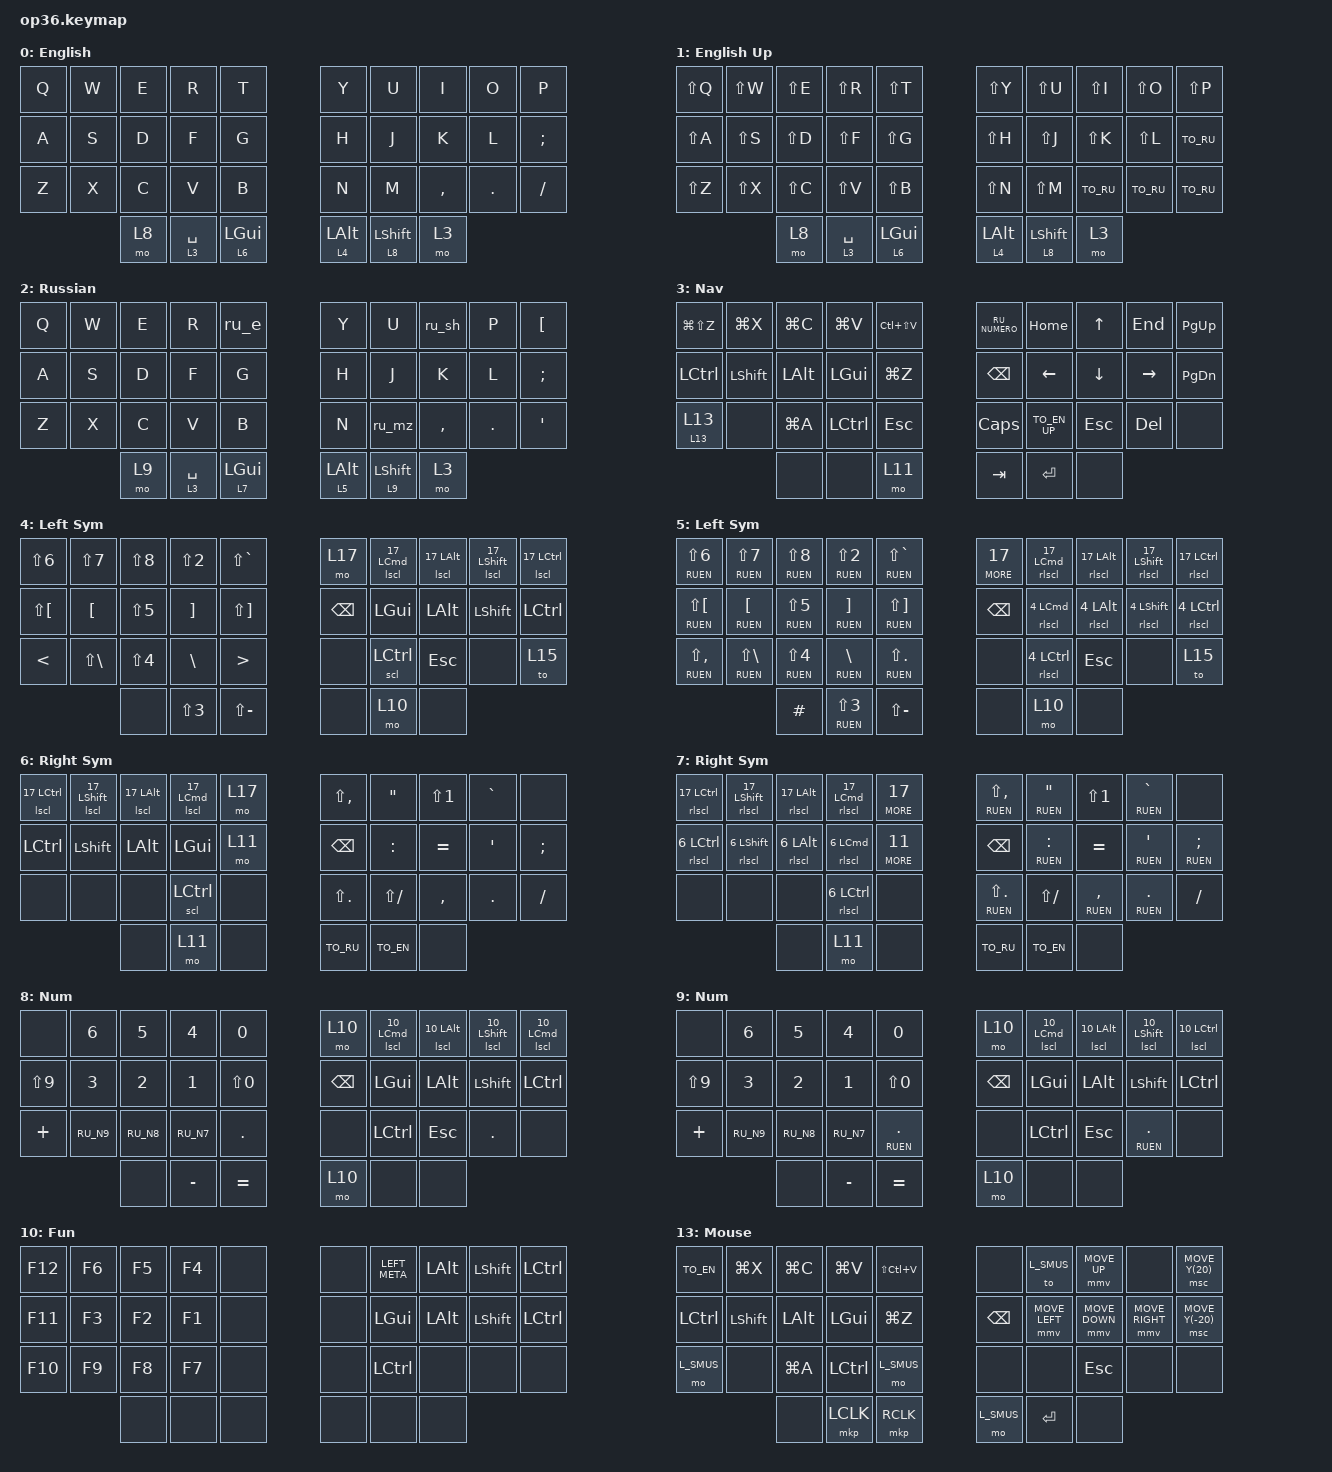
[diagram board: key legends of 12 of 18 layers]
#include "keys_ru.h"
#include <behaviors.dtsi>
#include <dt-bindings/zmk/bt.h>
#include <dt-bindings/zmk/keys.h>
#include <dt-bindings/zmk/outputs.h>
#include <dt-bindings/zmk/pointing.h>

#define L_SMUS 16
#define L_SHORTCUTS 17

&mt {
    quick-tap-ms = <200>;
    flavor = "tap-preferred";
    require-prior-idle-ms = <125>;
};

&sk {
    release-after-ms = <2000>;
    quick-release;
};

&sl { release-after-ms = <2000>; };

/ {
    behaviors {
        hml: home_row_mod_left {
            compatible = "zmk,behavior-hold-tap";
            #binding-cells = <2>;
            flavor = "balanced";
            require-prior-idle-ms = <150>;
            tapping-term-ms = <280>;
            quick-tap-ms = <175>;
            bindings = <&kp>, <&kp>;

            hold-trigger-key-positions = <5 6 7 8 9 15 16 17 18 19 25 26 27 28 29 33 34 35>;
            hold-trigger-on-release;
        };

        hmr: home_row_mod_right {
            compatible = "zmk,behavior-hold-tap";
            #binding-cells = <2>;
            flavor = "balanced";
            require-prior-idle-ms = <150>;
            tapping-term-ms = <280>;
            quick-tap-ms = <175>;
            bindings = <&kp>, <&kp>;

            hold-trigger-key-positions = <0 1 2 3 4 10 11 12 13 14 20 21 22 23 24 30 31 32>;
            hold-trigger-on-release;
        };

        mosk: mosk {
            compatible = "zmk,behavior-hold-tap";
            #binding-cells = <2>;
            flavor = "hold-preferred";
            require-prior-idle-ms = <150>;
            tapping-term-ms = <280>;
            quick-tap-ms = <175>;
            bindings = <&mo>, <&sk>;

            label = "MOSK";
        };

        mosl: mosl {
            compatible = "zmk,behavior-hold-tap";
            #binding-cells = <2>;
            flavor = "hold-preferred";
            require-prior-idle-ms = <150>;
            tapping-term-ms = <280>;
            quick-tap-ms = <175>;
            bindings = <&mo>, <&sl>;

            label = "MOSL";
        };

        ru_sh: ru_sh {
            compatible = "zmk,behavior-mod-morph";
            label = "RU_SH";
            bindings = <&kp I>, <&kp O>;

            #binding-cells = <0>;
            mods = <(MOD_LALT)>;
            keep-mods = <(MOD_LSFT)>;
        };

        ru_mz: ru_mz {
            compatible = "zmk,behavior-mod-morph";
            label = "RU_MZ";
            bindings = <&kp M>, <&kp RIGHT_BRACKET>;

            #binding-cells = <0>;
            mods = <(MOD_LALT)>;
            keep-mods = <(MOD_LSFT)>;
        };

        ru_e: ru_e {
            compatible = "zmk,behavior-mod-morph";
            label = "RU_E";
            bindings = <&kp T>, <&kp BACKSLASH>;

            #binding-cells = <0>;
            mods = <(MOD_LALT)>;
            keep-mods = <(MOD_LSFT)>;
        };

        ml: mod_layer {
            compatible = "zmk,behavior-hold-tap";
            label = "MOD_LAYER";
            bindings = <&mo>, <&kp>;

            #binding-cells = <2>;
            tapping-term-ms = <200>;
        };

        smmv: smmv {
            compatible = "zmk,behavior-input-two-axis";
            label = "SMMV";
            #binding-cells = <1>;
            x-input-code = <INPUT_REL_X>;
            y-input-code = <INPUT_REL_Y>;
            time-to-max-speed-ms = <300>;
            acceleration-exponent = <1>;
        };

        mrsk: mrsk {
            compatible = "zmk,behavior-hold-tap";
            #binding-cells = <2>;
            flavor = "balanced";
            require-prior-idle-ms = <150>;
            tapping-term-ms = <280>;
            quick-tap-ms = <175>;
            bindings = <&MORE>, <&sk>;

            label = "MRSK";
            hold-trigger-on-release;
            hold-trigger-key-positions = <5 15 16 6 5 6 7 8 9 15 16 17 18 19 25 26 27 28 29 33 34 35>;
        };

        tomo: to_mo_layer {
            compatible = "zmk,behavior-hold-tap";
            #binding-cells = <2>;
            flavor = "hold-preferred";

            // Без привязки к таймингам: огромный tapping-term фактически отключает
            // таймаут, поэтому hold/tap решается не временем, а нажатием другой
            // клавиши. Нажал клавишу мыши -> momentary-слой (&mo); одиночный тап
            // любой длительности без других клавиш -> полное переключение (&to).

            tapping-term-ms = <60000>;
            bindings = <&mo>, <&to>;

            label = "TOMO";
        };
    };

    combos { compatible = "zmk,combos"; };

    macros {
        RUEN: RUEN {
            compatible = "zmk,behavior-macro-one-param";
            #binding-cells = <1>;
            bindings = <&kp LA(LC(LS(LG(E)))) &macro_param_1to1 &kp MACRO_PLACEHOLDER &kp LS(LA(LC(LG(R))))>;
            label = "RUEN";
        };

        TO_RU: TO_RU {
            compatible = "zmk,behavior-macro";
            #binding-cells = <0>;
            bindings = <&kp LS(LG(LC(LA(R)))) &to 2>;
            label = "TO_RU";
        };

        TO_EN: TO_EN {
            compatible = "zmk,behavior-macro";
            #binding-cells = <0>;
            bindings = <&kp LS(LG(LC(LA(E)))) &to 0>;
            label = "TO_EN";
        };

        TO_EN_UP: TO_EN_UP {
            compatible = "zmk,behavior-macro";
            #binding-cells = <0>;
            bindings = <&kp LS(LG(LC(LA(E)))) &to 1>;
            label = "TO_EN_UP";
        };

        scl: shortcut_mod {
            compatible = "zmk,behavior-macro-one-param";
            #binding-cells = <1>;
            bindings =
                <&macro_press>,
                <&mo L_SHORTCUTS &macro_param_1to1 &kp MACRO_PLACEHOLDER>,
                <&macro_pause_for_release>,
                <&macro_release>,
                <&mo L_SHORTCUTS &macro_param_1to1 &kp MACRO_PLACEHOLDER>;

            label = "SHORTCUT_MOD";
        };

        lscl: lscl {
            compatible = "zmk,behavior-macro-two-param";
            #binding-cells = <2>;
            bindings =
                <&macro_press>,
                <&macro_param_1to1 &mo MACRO_PLACEHOLDER &macro_param_2to1 &kp MACRO_PLACEHOLDER>,
                <&macro_pause_for_release>,
                <&macro_release>,
                <&macro_param_2to1 &kp MACRO_PLACEHOLDER &macro_param_1to1 &mo MACRO_PLACEHOLDER>;

            label = "LSCL";
        };

        rscl: ru_shortcut_mod {
            compatible = "zmk,behavior-macro-one-param";
            #binding-cells = <1>;
            bindings =
                <&macro_tap>,
                <&kp LS(LG(LC(LA(E))))>,
                <&macro_press>,
                <&mo L_SHORTCUTS &macro_param_1to1 &kp MACRO_PLACEHOLDER>,
                <&macro_pause_for_release>,
                <&macro_release>,
                <&mo L_SHORTCUTS &macro_param_1to1 &kp MACRO_PLACEHOLDER>,
                <&macro_tap>,
                <&kp LS(LG(LC(LA(R))))>;

            label = "RU_SHORTCUT_MOD";
        };

        rlscl: ru_lscl {
            compatible = "zmk,behavior-macro-two-param";
            #binding-cells = <2>;
            bindings =
                <&macro_tap>,
                <&kp LS(LG(LC(LA(E))))>,
                <&macro_press>,
                <&macro_param_1to1 &mo MACRO_PLACEHOLDER &macro_param_2to1 &kp MACRO_PLACEHOLDER>,
                <&macro_pause_for_release>,
                <&macro_release>,
                <&macro_param_2to1 &kp MACRO_PLACEHOLDER &macro_param_1to1 &mo MACRO_PLACEHOLDER>,
                <&macro_tap>,
                <&kp LS(LG(LC(LA(R))))>;

            label = "RU_LSCL";
        };

        MORE: MORE {
            compatible = "zmk,behavior-macro-one-param";
            #binding-cells = <1>;
            bindings =
                <&macro_tap>,
                <&kp LA(LC(LS(LG(E))))>,
                <&macro_press>,
                <&macro_param_1to1 &mo MACRO_PLACEHOLDER>,
                <&macro_pause_for_release>,
                <&macro_release>,
                <&macro_param_1to1 &mo MACRO_PLACEHOLDER>,
                <&macro_tap>,
                <&kp LS(LA(LC(LG(R))))>;

            label = "MORE";
        };
    };

    keymap {
        compatible = "zmk,keymap";

        ENG {
            display-name = "English";
            bindings = <
  &kp Q  &kp W  &kp E  &kp R  &kp T                                              &kp Y               &kp U  &kp I      &kp O    &kp P
  &kp A  &kp S  &kp D  &kp F  &kp G                                              &kp H               &kp J  &kp K      &kp L    &kp SEMI
  &kp Z  &kp X  &kp C  &kp V  &kp B                                              &kp N               &kp M  &kp COMMA  &kp DOT  &kp FSLH
                       &mo 8  &lt 3 SPACE  &mosk 6 LEFT_GUI    &mosk 4 LEFT_ALT  &mosk 8 LEFT_SHIFT  &mo 3
            >;
        };

        ENG_UP {
            display-name = "English Up";
            bindings = <
  &kp LS(Q)  &kp LS(W)  &kp LS(E)  &kp LS(R)  &kp LS(T)                                          &kp LS(Y)           &kp LS(U)  &kp LS(I)  &kp LS(O)  &kp LS(P)
  &kp LS(A)  &kp LS(S)  &kp LS(D)  &kp LS(F)  &kp LS(G)                                          &kp LS(H)           &kp LS(J)  &kp LS(K)  &kp LS(L)  &TO_RU
  &kp LS(Z)  &kp LS(X)  &kp LS(C)  &kp LS(V)  &kp LS(B)                                          &kp LS(N)           &kp LS(M)  &TO_RU     &TO_RU     &TO_RU
                                   &mo 8      &lt 3 SPACE  &mosk 6 LEFT_GUI    &mosk 4 LEFT_ALT  &mosk 8 LEFT_SHIFT  &mo 3
            >;
        };

        RUS {
            display-name = "Russian";
            bindings = <
  &kp Q  &kp W  &kp E  &kp R  &ru_e                                              &kp Y               &kp U   &ru_sh     &kp P    &kp LEFT_BRACKET
  &kp A  &kp S  &kp D  &kp F  &kp G                                              &kp H               &kp J   &kp K      &kp L    &kp SEMI
  &kp Z  &kp X  &kp C  &kp V  &kp B                                              &kp N               &ru_mz  &kp COMMA  &kp DOT  &kp SQT
                       &mo 9  &lt 3 SPACE  &mosk 7 LEFT_GUI    &mosk 5 LEFT_ALT  &mosk 9 LEFT_SHIFT  &mo 3
            >;
        };

        NAV {
            bindings = <
  &kp LG(LS(Z))     &kp LG(X)       &kp LG(C)     &kp LG(V)         &kp LC(LS(V))                     &kp RU_NUMERO  &kp HOME        &kp UP      &kp END     &kp PAGE_UP
  &kp LEFT_CONTROL  &kp LEFT_SHIFT  &kp LEFT_ALT  &kp LEFT_GUI      &kp LG(Z)                         &kp BACKSPACE  &kp LEFT_ARROW  &kp DOWN    &kp RIGHT   &kp PAGE_DOWN
  &tomo 13 13       &none           &kp LG(A)     &kp LEFT_CONTROL  &kp ESC                           &kp CAPSLOCK   &TO_EN_UP       &kp ESCAPE  &kp DELETE  &none
                                                  &none             &none          &mo 11    &kp TAB  &kp ENTER      &none
            >;

            display-name = "Nav";
        };

        LSM_EN {
            bindings = <
  &kp LS(N6)            &kp LS(N7)         &kp LS(N8)        &kp LS(NUMBER_2)   &kp LS(GRAVE)                                  &mo 17         &lscl 17 LEFT_COMMAND  &lscl 17 LEFT_ALT  &lscl 17 LEFT_SHIFT  &lscl 17 LEFT_CONTROL
  &kp LS(LEFT_BRACKET)  &kp LEFT_BRACKET   &kp LS(NUMBER_5)  &kp RIGHT_BRACKET  &kp LS(RIGHT_BRACKET)                          &kp BACKSPACE  &kp LEFT_GUI           &kp LEFT_ALT       &kp LEFT_SHIFT       &kp LEFT_CONTROL
  &kp LESS_THAN         &kp LS(BACKSLASH)  &kp LS(NUMBER_4)  &kp BACKSLASH      &kp GREATER_THAN                               &none          &scl LEFT_CONTROL      &kp ESC            &none                &to 15
                                                             &none              &kp LS(NUMBER_3)       &kp LS(MINUS)    &none  &mo 10         &none
            >;

            label = "Left Sym";
        };

        LSM_RU {
            bindings = <
  &RUEN LS(N6)            &RUEN LS(N7)         &RUEN LS(N8)        &RUEN LS(NUMBER_2)   &RUEN LS(GRAVE)                                  &MORE 17       &rlscl 17 LEFT_COMMAND  &rlscl 17 LEFT_ALT  &rlscl 17 LEFT_SHIFT  &rlscl 17 LEFT_CONTROL
  &RUEN LS(LEFT_BRACKET)  &RUEN LEFT_BRACKET   &RUEN LS(NUMBER_5)  &RUEN RIGHT_BRACKET  &RUEN LS(RIGHT_BRACKET)                          &kp BACKSPACE  &rlscl 4 LEFT_COMMAND   &rlscl 4 LEFT_ALT   &rlscl 4 LEFT_SHIFT   &rlscl 4 LEFT_CONTROL
  &RUEN LS(COMMA)         &RUEN LS(BACKSLASH)  &RUEN LS(NUMBER_4)  &RUEN BACKSLASH      &RUEN LS(DOT)                                    &none          &rlscl 4 LEFT_CONTROL   &kp ESC             &none                 &to 15
                                                                   &kp HASH             &RUEN LS(NUMBER_3)       &kp LS(MINUS)    &none  &mo 10         &none
            >;

            label = "Left Sym";
        };

        RSM_EN {
            bindings = <
  &lscl 17 LEFT_CONTROL  &lscl 17 LEFT_SHIFT  &lscl 17 LEFT_ALT  &lscl 17 LEFT_COMMAND  &mo 17                   &kp LS(COMMA)  &kp DQT       &kp LS(N1)  &kp GRAVE         &none
  &kp LEFT_CONTROL       &kp LEFT_SHIFT       &kp LEFT_ALT       &kp LEFT_GUI           &mo 11                   &kp BACKSPACE  &kp COLON     &kp EQUAL   &kp SINGLE_QUOTE  &kp SEMI
  &none                  &none                &none              &scl LEFT_CONTROL      &none                    &kp LS(DOT)    &kp LS(FSLH)  &kp COMMA   &kp DOT           &kp FSLH
                                                                 &none                  &mo 11  &none    &TO_RU  &TO_EN         &none
            >;

            label = "Right Sym";
        };

        RSM_RU {
            bindings = <
  &rlscl 17 LEFT_CONTROL  &rlscl 17 LEFT_SHIFT  &rlscl 17 LEFT_ALT  &rlscl 17 LEFT_COMMAND  &MORE 17                   &RUEN LS(COMMA)  &RUEN DQT     &kp LS(N1)   &RUEN GRAVE         &none
  &rlscl 6 LEFT_CONTROL   &rlscl 6 LEFT_SHIFT   &rlscl 6 LEFT_ALT   &rlscl 6 LEFT_COMMAND   &MORE 11                   &kp BACKSPACE    &RUEN COLON   &kp EQUAL    &RUEN SINGLE_QUOTE  &RUEN SEMI
  &none                   &none                 &none               &rlscl 6 LEFT_CONTROL   &none                      &RUEN LS(DOT)    &kp LS(FSLH)  &RUEN COMMA  &RUEN DOT           &kp FSLH
                                                                    &none                   &mo 11    &none    &TO_RU  &TO_EN           &none
            >;

            label = "Right Sym";
        };

        NUM_EN {
            bindings = <
  &none       &kp N6        &kp NUMBER_5  &kp NUMBER_4  &kp N0                           &mo 10         &lscl 10 LEFT_COMMAND  &lscl 10 LEFT_ALT  &lscl 10 LEFT_SHIFT  &lscl 10 LEFT_COMMAND
  &kp LS(N9)  &kp NUMBER_3  &kp NUMBER_2  &kp N1        &kp LS(N0)                       &kp BACKSPACE  &kp LEFT_GUI           &kp LEFT_ALT       &kp LEFT_SHIFT       &kp LEFT_CONTROL
  &kp PLUS    &kp RU_N9     &kp RU_N8     &kp RU_N7     &kp DOT                          &none          &kp LEFT_CONTROL       &kp ESC            &kp DOT              &none
                                          &none         &kp MINUS   &kp EQUAL    &mo 10  &none          &none
            >;

            label = "Num";
        };

        NUM_RU {
            bindings = <
  &none       &kp N6        &kp NUMBER_5  &kp NUMBER_4  &kp N0                           &mo 10         &lscl 10 LEFT_COMMAND  &lscl 10 LEFT_ALT  &lscl 10 LEFT_SHIFT  &lscl 10 LEFT_CONTROL
  &kp LS(N9)  &kp NUMBER_3  &kp NUMBER_2  &kp N1        &kp LS(N0)                       &kp BACKSPACE  &kp LEFT_GUI           &kp LEFT_ALT       &kp LEFT_SHIFT       &kp LEFT_CONTROL
  &kp PLUS    &kp RU_N9     &kp RU_N8     &kp RU_N7     &RUEN DOT                        &none          &kp LEFT_CONTROL       &kp ESC            &RUEN DOT            &none
                                          &none         &kp MINUS   &kp EQUAL    &mo 10  &none          &none
            >;

            label = "Num";
        };

        FUN {
            bindings = <
  &kp F12  &kp F6  &kp F5  &kp F4  &none                  &none  &kp LEFT_META     &kp LEFT_ALT  &kp LEFT_SHIFT  &kp LEFT_CONTROL
  &kp F11  &kp F3  &kp F2  &kp F1  &none                  &none  &kp LEFT_GUI      &kp LEFT_ALT  &kp LEFT_SHIFT  &kp LEFT_CONTROL
  &kp F10  &kp F9  &kp F8  &kp F7  &none                  &none  &kp LEFT_CONTROL  &none         &none           &none
                           &none   &none  &none    &none  &none  &none
            >;

            label = "Fun";
        };

        APP {
            bindings = <
  &none  &none  &none  &none  &none                  &kp LS(LA(LC(LG(Y))))  &kp LG(LA(ESCAPE))  &kp LG(LA(N0))  &kp LA(LC(LG(LS(O))))  &kp LC(LG(SPACE))
  &none  &none  &none  &none  &none                  &kp LG(LA(F1))         &kp LG(LA(F2))      &kp LG(LA(F3))  &kp LG(LA(F4))         &kp LG(LA(F5))
  &none  &none  &none  &none  &none                  &kp LA(LG(F6))         &kp LA(LG(F7))      &kp LA(LG(F8))  &kp LA(LG(F9))         &kp LA(LG(F10))
                       &none  &none  &none    &none  &none                  &none
            >;

            label = "App";
        };

        IDE {
            bindings = <
  &none            &none  &kp LC(F1)     &kp LC(LA(R))  &kp LC(LG(LA(T)))                  &kp LG(F2)  &kp LA(F7)     &kp LG(LA(B))  &none          &kp LG(F8)
  &kp LG(LS(A))    &none  &kp LG(O)      &kp LG(LS(F))  &kp LS(LG(O))                      &none       &kp LC(LS(J))  &none          &kp LG(LC(L))  &none
  &kp LS(LG(F12))  &none  &kp LG(LA(C))  &kp LG(LA(V))  &none                              &kp LS(F6)  &kp LG(LA(M))  &none          &none          &none
                                         &none          &none              &none    &none  &none       &none
            >;

            label = "IDE";
        };

        MUS {
            bindings = <
  &TO_EN            &kp LG(X)       &kp LG(C)     &kp LG(V)         &kp LS(LC(V))                           &none          &to L_SMUS      &mmv MOVE_UP    &none            &msc MOVE_Y(20)
  &kp LEFT_CONTROL  &kp LEFT_SHIFT  &kp LEFT_ALT  &kp LEFT_GUI      &kp LG(Z)                               &kp BACKSPACE  &mmv MOVE_LEFT  &mmv MOVE_DOWN  &mmv MOVE_RIGHT  &msc MOVE_Y(-20)
  &mo L_SMUS        &none           &kp LG(A)     &kp LEFT_CONTROL  &mo L_SMUS                              &none          &none           &kp ESC         &none            &none
                                                  &none             &mkp LCLK      &mkp RCLK    &mo L_SMUS  &kp ENTER      &none
            >;

            label = "Mouse";
        };

        KAN {
            bindings = <
  &lt 15 Q  &kp W  &kp E  &kp R       &kp T                                    &kp Y           &kp U             &kp I      &kp O    &kp P
  &kp A     &kp S  &kp D  &kp F       &kp G                                    &kp H           &kp J             &kp K      &kp L    &kp SEMI
  &kp Z     &kp X  &kp C  &kp V       &kp B                                    &kp N           &kp M             &kp COMMA  &kp DOT  &kp FSLH
                          &kp ESCAPE  &kp SPACE  &kp LEFT_GUI    &kp LEFT_ALT  &kp LEFT_SHIFT  &kp LEFT_CONTROL
            >;

            display-name = "Kanata";
        };

        SETUP {
            bindings = <
  &TO_EN  &none  &none  &none  &none                  &bt BT_SEL 0  &bt BT_SEL 1  &bt BT_SEL 2  &bt BT_SEL 3  &bt BT_CLR
  &none   &none  &none  &none  &none                  &out OUT_BLE  &kp C_VOL_DN  &kp C_MUTE    &kp C_VOL_UP  &kp RGUI
  &none   &none  &none  &none  &none                  &out OUT_USB  &kp C_PREV    &kp C_PP      &kp C_NEXT    &studio_unlock
                        &none  &none  &none    &none  &none         &none
            >;

            display-name = "Setup";
        };

        SMUS {
            bindings = <
  &TO_EN            &kp LG(X)       &kp LG(C)     &kp LG(V)         &kp LS(LC(V))                      &none          &none              &mmv MOVE_Y(-150)  &to 13            &msc SCRL_UP
  &kp LEFT_CONTROL  &kp LEFT_SHIFT  &kp LEFT_ALT  &kp LEFT_GUI      &kp LG(Z)                          &kp BACKSPACE  &mmv MOVE_X(-150)  &mmv MOVE_Y(150)   &mmv MOVE_X(150)  &msc SCRL_DOWN
  &none             &none           &kp LG(A)     &kp LEFT_CONTROL  &none                              &none          &none              &kp ESC            &none             &none
                                                  &none             &mkp LCLK      &mkp RCLK    &none  &kp ENTER      &none
            >;

            label = "Slow Mouse";
        };

        SHOTCUTS {
            display-name = "Shortcuts";
            bindings = <
  &hml LEFT_CONTROL Q  &hml LEFT_SHIFT W  &hml LEFT_ALT E  &hml LEFT_COMMAND R  &kp T                        &kp Y      &hmr LEFT_COMMAND U  &hmr LEFT_ALT I  &hmr LEFT_SHIFT O  &hmr LEFT_CONTROL P
  &kp A                &kp S              &kp D            &kp F                &kp G                        &kp H      &kp J                &kp K            &kp L              &kp SEMI
  &kp Z                &kp X              &kp C            &kp V                &kp B                        &kp N      &kp M                &kp COMMA        &kp DOT            &kp FSLH
                                                           &none                &kp SPACE  &none    &kp TAB  &kp ENTER  &none
            >;
        };
    };
};
